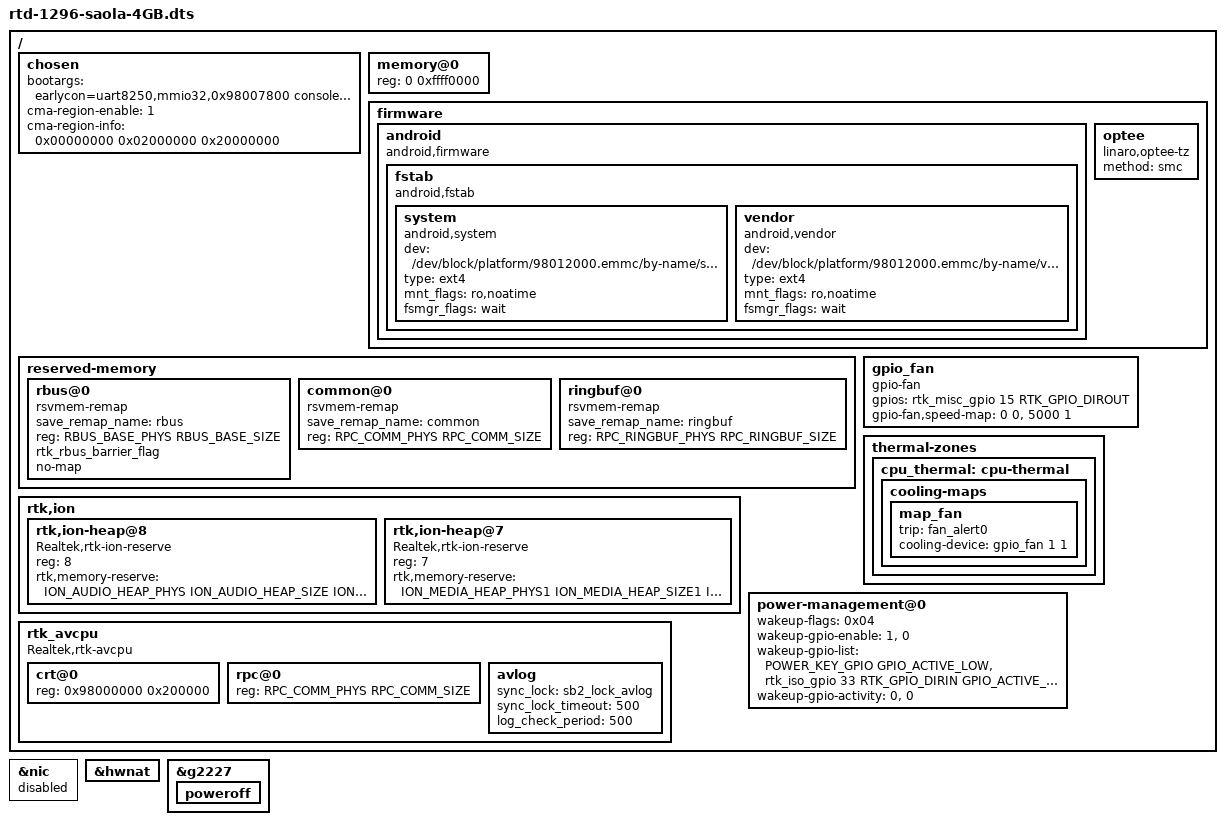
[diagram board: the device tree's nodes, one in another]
/dts-v1/;
#include <dt-bindings/soc/rtd129x,memory.h>
#include <dt-bindings/gpio/gpio.h>

/* 0x00000000 ~ 0x0002ffff */
/memreserve/ SYS_BOOTCODE_MEMBASE SYS_BOOTCODE_MEMSIZE;
/* 0x0001f000 ~ 0x0001ffff */
/memreserve/ RPC_COMM_PHYS RPC_COMM_SIZE;
/* 0x01b00000 ~ 0x01efffff ACPU_FIREWARE_PHYS ACPU_FIREWARE_SIZE */
/memreserve/ 0x01B00000 0x00400000;
/* 0x01ffe000 ~ 0x02001fff */
/memreserve/ RPC_RINGBUF_PHYS	 RPC_RINGBUF_SIZE;
/* 0x02200000 ~ 0x025fffff */
/memreserve/ ROOTFS_NORMAL_START ROOTFS_NORMAL_SIZE;
/* 0x02600000 ~ 0x031fffff */
/memreserve/ ION_AUDIO_HEAP_PHYS ION_AUDIO_HEAP_SIZE;
/* 0x03200000 ~ 0x0e9fffff */
/memreserve/ ION_MEDIA_HEAP_PHYS1  ION_MEDIA_HEAP_SIZE1;
/* 0x10000000 ~ 0x10013fff */
/memreserve/ ACPU_IDMEM_PHYS ACPU_IDMEM_SIZE;
/* 0x11000000 ~ 0x181fffff */
/memreserve/ ION_MEDIA_HEAP_PHYS2 ION_MEDIA_HEAP_SIZE2;
/* 0x7fff0000 ~ 0x7fffffff */
/memreserve/ HW_LIMITATION_3GB_START HW_LIMITATION_3GB_SIZE;
/* 0x80000000 ~ 0x80007fff */
/memreserve/ HW_SECURE_RAM_START HW_SECURE_RAM_SIZE;
/* 0x88100000 ~ 0x8A0FFFFF */
/memreserve/ HW_NOR_REMAP_START HW_NOR_REMAP_SIZE;
/* HW_JTAG_GIC_RSV */
/memreserve/ 0xFF000000 0x00800000;

#include "rtd-1296-saola-common.dtsi"

#define RTK_GPIO_DIRIN 0
#define RTK_GPIO_DIROUT 1

#define POWER_KEY_GPIO &rtk_iso_gpio 5 RTK_GPIO_DIRIN

/ {
	chosen {
		bootargs = "earlycon=uart8250,mmio32,0x98007800 console=ttyS0,115200 loglevel=7";
	};

	/*
	 * NOTE:
	 * <flag size base>
	 * flag: reserved
	 * size: unit is byte
	 * base: unit is byte
	 *
	 * Array size not over 8;
	 * You may change the max array size in KConfig,
	 * max CMA array size is CONFIG_CMA_AREAS+1.
	 *
	 * If cma-region-enable is enabled<1>,
	 * kernel driver will use cma-region-info to initial CMA memory.
	 *
	 * If cma-region-enable is disabled<0>,
	 * kernel driver will use cma= to initial CMA memory.
	 *
	 * if both setting is loaded, cma-region-info had higher priority.
	 */
	chosen {
		cma-region-enable = <1>;
		cma-region-info = <0x00000000 0x02000000 0x20000000>;
		/*cma-region-info = <0x00000000 0x01000000 0x12c00000>,
			<0x00000000 0x12c00000 0x20000000>;*/
	};

	memory@0 {
		device_type = "memory";
		reg = <0 0xffff0000>; /* 4096 MB */
	};

	firmware {
		android {
			compatible = "android,firmware";
			fstab {
				compatible = "android,fstab";
				system {
					compatible = "android,system";
					dev = "/dev/block/platform/98012000.emmc/by-name/system";
					type = "ext4";
					mnt_flags = "ro,noatime";
					fsmgr_flags = "wait";
				};
				vendor {
					compatible = "android,vendor";
					dev = "/dev/block/platform/98012000.emmc/by-name/vendor";
					type = "ext4";
					mnt_flags = "ro,noatime";
					fsmgr_flags = "wait";
				};
			};
		};
		optee {
			compatible = "linaro,optee-tz";
			method = "smc";
		};
	};

	reserved-memory {
		#address-cells = <1>;
		#size-cells = <1>;
		ranges;

		rbus@0 {
			compatible = "rsvmem-remap";
			save_remap_name = "rbus";
			reg = <RBUS_BASE_PHYS RBUS_BASE_SIZE>;
			rtk_rbus_barrier_flag;
			no-map;
		};

		common@0 {
			compatible = "rsvmem-remap";
			save_remap_name = "common";
			reg = <RPC_COMM_PHYS RPC_COMM_SIZE>;
		};

		ringbuf@0 {
			compatible = "rsvmem-remap";
			save_remap_name = "ringbuf";
			reg = <RPC_RINGBUF_PHYS RPC_RINGBUF_SIZE>;
		};
	};

	rtk,ion {
		rtk,ion-heap@8 { /* Audio */
			compatible = "Realtek,rtk-ion-reserve";
			reg = <8>;
			rtk,memory-reserve = <
				ION_AUDIO_HEAP_PHYS
				ION_AUDIO_HEAP_SIZE
				ION_AUDIO_HEAP_FLAG>;
	};

	rtk,ion-heap@7 { /* TYPE_MEDIA */
		compatible = "Realtek,rtk-ion-reserve";
			reg = <7>;
			rtk,memory-reserve = <
				ION_MEDIA_HEAP_PHYS1
				ION_MEDIA_HEAP_SIZE1
				ION_MEDIA_HEAP_FLAG1
				ION_MEDIA_HEAP_PHYS2
				ION_MEDIA_HEAP_SIZE2
				ION_MEDIA_HEAP_FLAG2>;
		};
	};

	rtk_avcpu {
		compatible = "Realtek,rtk-avcpu";
		#address-cells = <1>;
		#size-cells = <1>;
		ranges;

		crt@0 {
			reg = <0x98000000 0x200000>;
		};

		rpc@0 {
			reg = <RPC_COMM_PHYS RPC_COMM_SIZE>;
		};

		avlog {
			sync_lock = <&sb2_lock_avlog>;
			sync_lock_timeout = <500>; /* ms */
			log_check_period = <500>; /* ms */
		};
	};

	gpio_fan: gpio_fan {
		compatible = "gpio-fan";
		gpios = <&rtk_misc_gpio 15 RTK_GPIO_DIROUT GPIO_ACTIVE_HIGH>;
		gpio-fan,speed-map = <0 0>,
				<5000 1>;
		#cooling-cells = <2>; /* min followed by max */
	};


	thermal-zones {
		cpu_thermal: cpu-thermal {
			cooling-maps {
				map_fan {
					trip = <&fan_alert0>;
					cooling-device = <&gpio_fan 1 1>;
				};
			};
		};
	};

	power-management@0 {
		/* system-power-controller; */

		wakeup-flags = <0x04>; /* only enable gpio wakeup, ref enum _wakeup_flags in rtd129x_suspend.h */
		/* GPIO Wakeup */
		wakeup-gpio-enable = /* (0) disable (1) enable */
			<1>,/* Wakeup from GPIO : enable */
			<0>; /* Wakeup from WiFi : disable */
		wakeup-gpio-list = /* <&rtk_iso_gpio {num} {force input (0) } {default N/A (0)] }> */
			<POWER_KEY_GPIO GPIO_ACTIVE_LOW>, /* GPIO wakeup host pin */
			<&rtk_iso_gpio 33 RTK_GPIO_DIRIN GPIO_ACTIVE_LOW>; /* WiFi wakeup host pin */
		wakeup-gpio-activity = /* (0) active low (1) active high*/
			<0>,/* GPIO : low activity */
			<0>; /* Wifi : low activity */
	};
};

&nic {
	status = "disabled";
};

&hwnat {
	status = "okay";
};

&g2227 {
	poweroff {
		status = "okay";
	};
};
